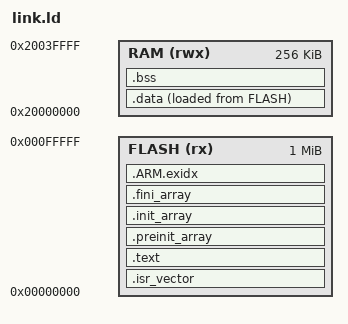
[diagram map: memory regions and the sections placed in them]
ENTRY(Reset_Handler)
MEMORY
{
  FLASH (rx)  : ORIGIN = 0x00000000, LENGTH = 1024K
  RAM   (rwx) : ORIGIN = 0x20000000, LENGTH = 256K
}
_estack = ORIGIN(RAM) + LENGTH(RAM);
SECTIONS
{
  .isr_vector : { KEEP(*(.isr_vector)) } > FLASH
  .text : { *(.text*) *(.rodata*) *(.init) *(.fini) . = ALIGN(4); } > FLASH
  .preinit_array : { PROVIDE_HIDDEN(__preinit_array_start = .); KEEP(*(.preinit_array*)) PROVIDE_HIDDEN(__preinit_array_end = .); } > FLASH
  .init_array : { PROVIDE_HIDDEN(__init_array_start = .); KEEP(*(SORT(.init_array.*))) KEEP(*(.init_array*)) PROVIDE_HIDDEN(__init_array_end = .); } > FLASH
  .fini_array : { PROVIDE_HIDDEN(__fini_array_start = .); KEEP(*(.fini_array*)) PROVIDE_HIDDEN(__fini_array_end = .); } > FLASH
  .ARM.exidx : { *(.ARM.exidx*) } > FLASH
  _sidata = LOADADDR(.data);
  .data : { _sdata = .; *(.data*) . = ALIGN(4); _edata = .; } > RAM AT > FLASH
  .bss (NOLOAD) : { _sbss = .; *(.bss*) *(COMMON) . = ALIGN(4); _ebss = .; } > RAM
  /DISCARD/ : { *(.ARM.extab*) }
}
